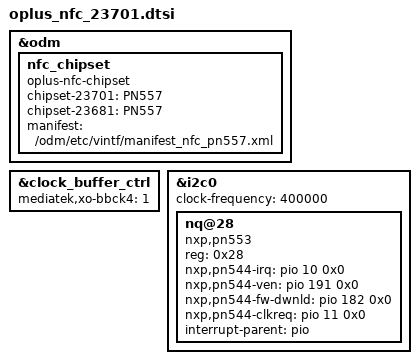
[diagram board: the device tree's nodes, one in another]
/**********************************************************************************
* Copyright (c)  2008-2020  Guangdong oplus Mobile Comm Corp., Ltd
*
***********************************************************************************/
&odm {
	nfc_chipset:nfc_chipset {
		compatible = "oplus-nfc-chipset";
		chipset-23701 = "PN557";
                chipset-23681 = "PN557";
                manifest = "/odm/etc/vintf/manifest_nfc_pn557.xml";
	};
};

&clock_buffer_ctrl {
	mediatek,xo-bbck4 = <1>;
};

&i2c0 {
       status = "okay";
       clock-frequency = <400000>;
       nq@28 {
               compatible = "nxp,pn553";
               reg = <0x28>;
               nxp,pn544-irq = <&pio 10 0x0>;
               nxp,pn544-ven = <&pio 191 0x0>;
               nxp,pn544-fw-dwnld = <&pio 182 0x0>;
	       nxp,pn544-clkreq = <&pio 11 0x0>;
               interrupt-parent = <&pio>;
       };
};
